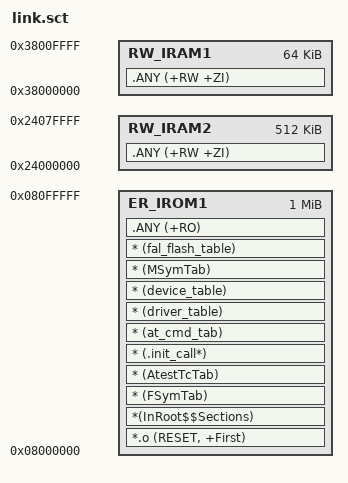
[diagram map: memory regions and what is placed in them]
; *************************************************************
; *** Scatter-Loading Description File generated by uVision ***
; *************************************************************

LR_IROM1 0x08000000 0x00100000  {    ; load region size_region
  ER_IROM1 0x08000000 0x00100000  {  ; load address = execution address
   *.o (RESET, +First)
   *(InRoot$$Sections)
   * (FSymTab)
   * (AtestTcTab)
   * (.init_call*)
   * (at_cmd_tab)
   * (driver_table)
   * (device_table)
   * (MSymTab)
   * (fal_flash_table)
   .ANY (+RO)
  }
  RW_IRAM1 0x38000000 0x00010000  {  ; RW data
   .ANY (+RW +ZI)
  }
  RW_IRAM2 0x24000000 0x00080000  {  ; RW data
   .ANY (+RW +ZI)
  }
}

